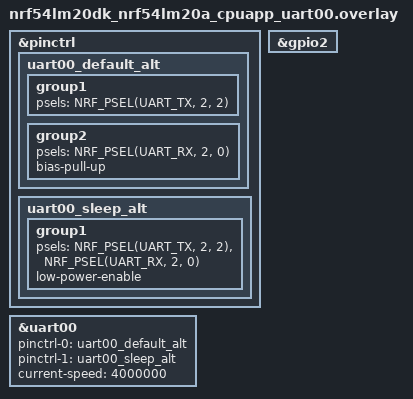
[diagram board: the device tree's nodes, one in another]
/*
 * Copyright (c) 2025 Nordic Semiconductor ASA
 *
 * SPDX-License-Identifier: Apache-2.0
 */

/* Test requires following loopback:
 * P2.02 - P2.00
 */

&pinctrl {
	uart00_default_alt: uart00_default_alt {
		group1 {
			psels = <NRF_PSEL(UART_TX, 2, 2)>;
		};

		group2 {
			psels = <NRF_PSEL(UART_RX, 2, 0)>;
			bias-pull-up;
		};
	};

	uart00_sleep_alt: uart00_sleep_alt {
		group1 {
			psels = <NRF_PSEL(UART_TX, 2, 2)>,
				<NRF_PSEL(UART_RX, 2, 0)>;
			low-power-enable;
		};
	};
};

dut: &uart00 {
	status = "okay";
	pinctrl-0 = <&uart00_default_alt>;
	pinctrl-1 = <&uart00_sleep_alt>;
	pinctrl-names = "default", "sleep";
	current-speed = <4000000>;
};

&gpio2 {
	status = "okay";
};
